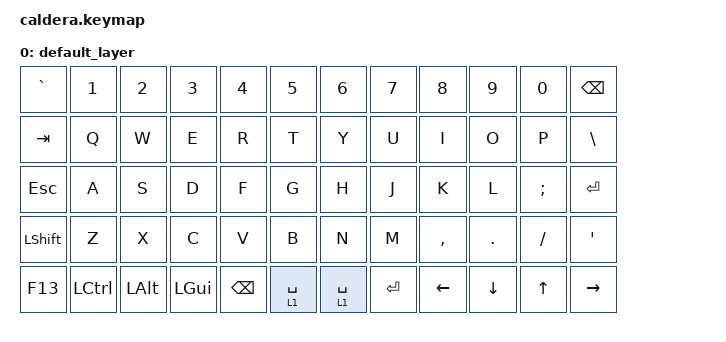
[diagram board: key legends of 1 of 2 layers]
#include <behaviors.dtsi>
#include <dt-bindings/zmk/bt.h>
#include <dt-bindings/zmk/keys.h>

/ {
    keymap {
        compatible = "zmk,keymap";

        default_layer {
            // ---------------------------------------------------------------------------------
            // |   `  |  1  |  2  |  3  |  4   |  5  |     |  6  |  7  |  8  |  9  |  0  | BKSP |
            // |  TAB |  Q  |  W  |  E  |  R   |  T  |     |  Y  |  U  |  I  |  O  |  P  |  \   |
            // |  ESC |  A  |  S  |  D  |  F   |  G  |     |  H  |  J  |  K  |  L  |  ;  |  ENT |
            // | SHFT |  Z  |  X  |  C  |  V   |  B  |     |  N  |  M  |  ,  |  .  |  /  |   '  |
            // |  F13 | CRT | ALT | GUI | BKSP | SPC |     | SPC | ENT |LARW |DARW |UARW | RARW |

            bindings = <
&kp GRAVE  &kp N1            &kp N2        &kp N3        &kp N4         &kp N5         &kp N6       &kp N7     &kp N8     &kp N9    &kp N0    &kp BSPC
&kp TAB    &kp Q             &kp W         &kp E         &kp R          &kp T          &kp Y        &kp U      &kp I      &kp O     &kp P     &kp BSLH
&kp ESC    &kp A             &kp S         &kp D         &kp F          &kp G          &kp H        &kp J      &kp K      &kp L     &kp SEMI  &kp RET
&kp LSHFT  &kp Z             &kp X         &kp C         &kp V          &kp B          &kp N        &kp M      &kp COMMA  &kp DOT   &kp FSLH  &kp APOS
&kp F13    &kp LEFT_CONTROL  &kp LEFT_ALT  &kp LEFT_GUI  &kp BACKSPACE  &lt 1 SPACE    &lt 1 SPACE  &kp ENTER  &kp LEFT   &kp DOWN  &kp UP    &kp RIGHT
            >;
        };

        lower_layer {
            // ----------------------------------------------------------------------------------------------------------
            // |       |  BT1 |  BT2  |  BT3  |  BT4  |  BT5  |          |       |       |       |       |       | BTCLR |
            // |       |      |       |       |       |       |          |       |       |       |       |       |       |
            // |       |VOL_UP|VOL_DWN| LPAR  | RPAR  |       |          |       | LBKT  | RBKT  |   -   |   +   |  SHFT |
            // |       |      |       |       |       |       |          |       |       |       |       |       |       |

            bindings = <
&trans  &bt BT_SEL 0  &bt BT_SEL 1       &bt BT_SEL 2  &bt BT_SEL 3  &bt BT_SEL 4    &trans  &trans            &trans    &trans     &trans     &bt BT_CLR
&trans  &trans        &trans             &trans        &trans        &trans          &trans  &trans            &trans    &trans     &trans     &trans
&trans  &kp C_VOL_UP  &kp C_VOLUME_DOWN  &kp LPAR      &kp RPAR      &trans          &trans  &kp LEFT_BRACKET  &kp RBKT  &kp MINUS  &kp EQUAL  &kp RIGHT_SHIFT
&trans  &trans        &trans             &trans        &trans        &trans          &trans  &trans            &trans    &trans     &trans     &trans
            >;
        };
    };
};
